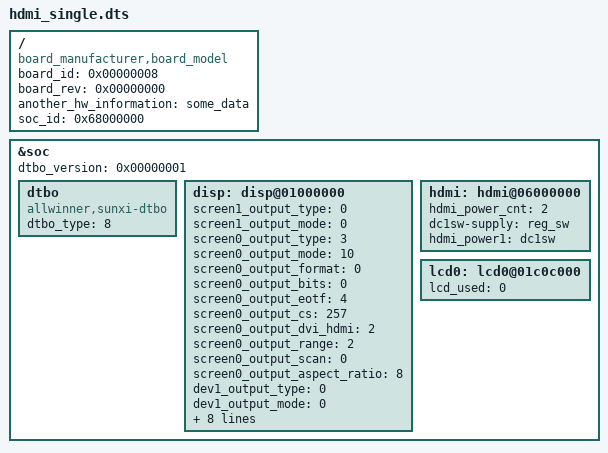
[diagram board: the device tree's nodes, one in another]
/dts-v1/;
/plugin/;

/ {

  compatible = "board_manufacturer,board_model";

  /* These properties are examples */
  board_id = <0x00000008>;
  board_rev = <0x00000000>;
  another_hw_information = "some_data";
  soc_id = <0x68000000>;

};

&soc {
	dtbo_version = <0x00000001>;
	dtbo{
		compatible = "allwinner,sunxi-dtbo";
		dtbo_type = <8>;
	};

	disp: disp@01000000 {
		screen1_output_type      = <0>;
		screen1_output_mode      = <0>;

		screen0_output_type      = <3>;
		screen0_output_mode      = <10>;

		screen0_output_format    = <0>;
		screen0_output_bits      = <0>;
		screen0_output_eotf      = <4>;
		screen0_output_cs        = <257>;
		screen0_output_dvi_hdmi  = <2>;
		screen0_output_range     = <2>;
		screen0_output_scan      = <0>;
		screen0_output_aspect_ratio = <8>;

		dev1_output_type         = <0>;
		dev1_output_mode         = <0>;
		dev1_screen_id           = <1>;
		dev1_do_hpd              = <1>;

		dev0_output_type         = <4>;
		dev0_output_mode         = <10>;
		dev0_screen_id           = <0>;
		dev0_do_hpd              = <1>;

		fb0_width                = <1920>;
		fb0_height               = <1080>;
	};

	hdmi: hdmi@06000000 {
		hdmi_power_cnt = <2>;
		dc1sw-supply = <&reg_sw>;
		hdmi_power1 = "dc1sw";
	};

	lcd0: lcd0@01c0c000 {
		lcd_used            = <0>;
	};
};
